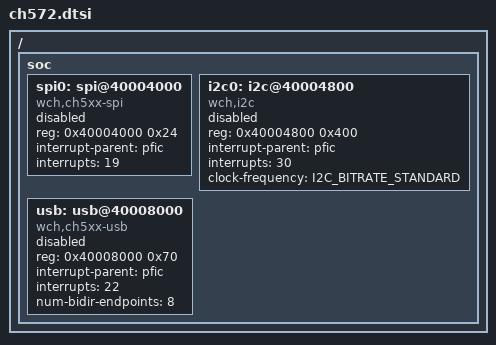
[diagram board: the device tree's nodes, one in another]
/*
 * SPDX-FileCopyrightText: 2026 SMILE (smile.eu)
 *
 * SPDX-License-Identifier: Apache-2.0
 */

#include <wch/ch57/ch570.dtsi>
#include <zephyr/dt-bindings/i2c/i2c.h>

/ {
	soc {
		spi0: spi@40004000 {
			compatible = "wch,ch5xx-spi";
			reg = <0x40004000 0x24>;
			interrupt-parent = <&pfic>;
			interrupts = <19>;
			#address-cells = <1>;
			#size-cells = <0>;
			status = "disabled";
		};

		i2c0: i2c@40004800 {
			compatible = "wch,i2c";
			reg = <0x40004800 0x400>;
			interrupt-parent = <&pfic>;
			interrupts = <30>;
			clock-frequency = <I2C_BITRATE_STANDARD>;
			#address-cells = <1>;
			#size-cells = <0>;
			status = "disabled";
		};

		usb: usb@40008000 {
			compatible = "wch,ch5xx-usb";
			reg = <0x40008000 0x70>;
			interrupt-parent = <&pfic>;
			interrupts = <22>;
			num-bidir-endpoints = <8>;
			status = "disabled";
		};
	};
};
